# S32M24x register map
Vendor: NXP Semiconductors; File version: 1.5
CPU: CM4 r0p1, little endian, MPU, FPU, VTOR, 4 interrupt priority bits
Registers are 32-bit, read-write, reset 0x0 unless marked. A register's access mark holds for its fields unless they carry their own. Offsets are from the block's base; [hi:lo] are bit positions; {n}, {i} and the like mark numbered series; 'fields as' and 'values as' point back to an identical list.

## PDB0 — PDB
Base 0x40036000
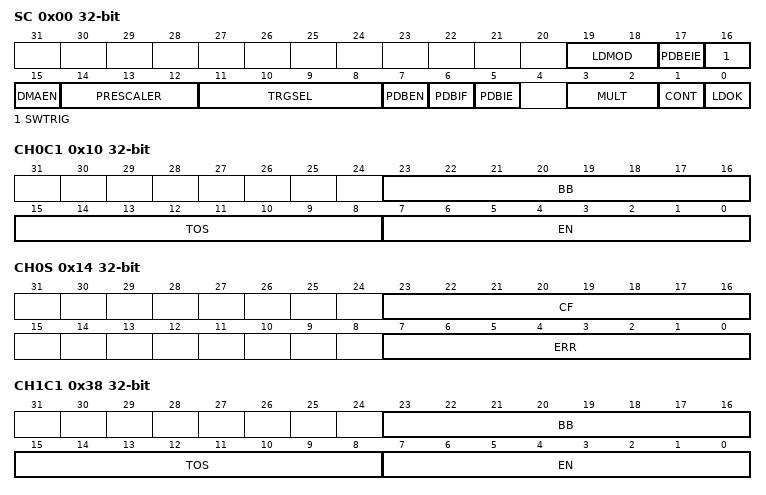
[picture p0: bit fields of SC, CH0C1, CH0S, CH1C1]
0x00 SC — Status and Control register
  [19:18] LDMOD — Load Mode Select
    0=The internal registers are loaded with the values from their buffers, immediately after 1 is written to LDOK; 1=The internal registers are loaded with the values from their buffers when the PDB counter (CNT) = MOD + 1 CNT delay elapsed, after 1 is written to LDOK; 2=The internal registers are loaded with the values from their buffers when a trigger input event is detected, after 1 is written to LDOK; 3=The internal registers are loaded with the values from their buffers when either the PDB counter (CNT) = MOD + 1 CNT delay elapsed, or a trigger input event is detected, after 1 is written to LDOK
  [17] PDBEIE — PDB Sequence Error Interrupt Enable
    0=PDB sequence error interrupt disabled; 1=PDB sequence error interrupt enabled
  [16] SWTRIG — Software Trigger
  [15] DMAEN — DMA Enable
    0=DMA disabled; 1=DMA enabled
  [14:12] PRESCALER — Prescaler Divider Select
    0=Counting uses the peripheral clock divided by MULT (the multiplication factor); 1=Counting uses the peripheral clock divided by 2 x MULT (the multiplication factor); 2=Counting uses the peripheral clock divided by 4 x MULT (the multiplication factor); 3=Counting uses the peripheral clock divided by 8 x MULT (the multiplication factor); 4=Counting uses the peripheral clock divided by 16 x MULT (the multiplication factor); 5=Counting uses the peripheral clock divided by 32 x MULT (the multiplication factor); 6=Counting uses the peripheral clock divided by 64 x MULT (the multiplication factor); 7=Counting uses the peripheral clock divided by 128 x MULT (the multiplication factor)
  [11:8] TRGSEL — Trigger Input Source Select
    {v}=Trigger-In {v} is selected (v=0..14); 15=Software trigger is selected
  [7] PDBEN — PDB Enable
    0=PDB disabled. Counter is off.; 1=PDB enabled
  [6] PDBIF — PDB Interrupt Flag
  [5] PDBIE — PDB Interrupt Enable
    0=PDB interrupt disabled; 1=PDB interrupt enabled
  [3:2] MULT — Multiplication Factor Select for Prescaler
    0=Multiplication factor is 1; 1=Multiplication factor is 10; 2=Multiplication factor is 20; 3=Multiplication factor is 40
  [1] CONT — Continuous Mode Enable
    0=PDB operation in One-Shot mode; 1=PDB operation in Continuous mode
  [0] LDOK — Load OK
0x04 MOD reset 0xFFFF — Modulus register
  [15:0] MOD — PDB Modulus
0x08 CNT ro — Counter register
  [15:0] CNT — PDB Counter
0x0C IDLY reset 0xFFFF — Interrupt Delay register
  [15:0] IDLY — PDB Interrupt Delay
0x10 CH0C1 — Channel n Control register 1
  [23:16] BB — PDB Channel Pre-Trigger Back-to-Back Operation Enable
    0=PDB channel's corresponding pre-trigger back-to-back operation disabled; 1=PDB channel's corresponding pre-trigger back-to-back operation enabled
  [15:8] TOS — PDB Channel Pre-Trigger Output Select
    0=PDB channel's corresponding pre-trigger is in bypassed mode. The pre-trigger asserts one peripheral clock cycle after a rising edge is detected on selected trigger input source or software trigger is selected and SWTRIG is written with 1.; 1=PDB channel's corresponding pre-trigger asserts when the counter reaches the channel delay register and one peripheral clock cycle after a rising edge is detected on selected trigger input source or software trigger is selected and SWTRIG is written with 1
  [7:0] EN — PDB Channel Pre-Trigger Enable
    0=PDB channel's corresponding pre-trigger disabled; 1=PDB channel's corresponding pre-trigger enabled
0x14 CH0S — Channel n Status register
  [23:16] CF — PDB Channel Flags
  [7:0] ERR — PDB Channel Sequence Error Flags
    0=Sequence error not detected on PDB channel's corresponding pre-trigger; 1=Sequence error detected on PDB channel's corresponding pre-trigger. ADCn block can be triggered for a conversion by one pre-trigger from PDB channel n. When one conversion, which is triggered by one of the pre-triggers from PDB channel n, is in progress, new trigger from PDB channel's corresponding pre-trigger m cannot be accepted by ADCn, and ERR[m] is set. Writing 0's to clear the sequence error flags.
0x18 CH0DLY0 — Channel n Delay 0 register
  [15:0] DLY — PDB Channel Delay
0x1C CH0DLY1 — Channel n Delay 1 register
  [15:0] DLY — PDB Channel Delay
0x38 CH1C1 — Channel n Control register 1
  fields as CH0C1
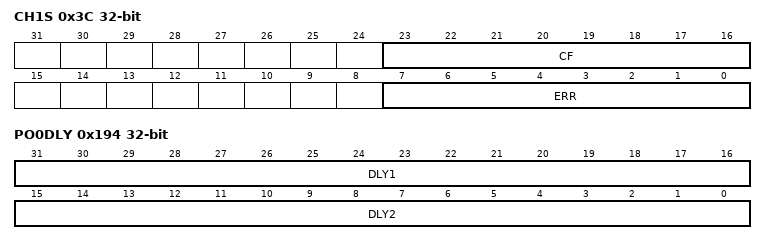
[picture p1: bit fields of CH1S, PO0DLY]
0x3C CH1S — Channel n Status register
  fields as CH0S
0x40 CH1DLY0 — Channel n Delay 0 register
  [15:0] DLY — PDB Channel Delay
0x44 CH1DLY1 — Channel n Delay 1 register
  [15:0] DLY — PDB Channel Delay
0x190 POEN — Pulse-Out n Enable register
  [7:0] POEN — PDB Pulse-Out Enable
    0=PDB Pulse-Out disabled; 1=PDB Pulse-Out enabled
0x194 PO0DLY — Pulse-Out n Delay register
  [31:16] DLY1 — PDB Pulse-Out Delay 1
  [15:0] DLY2 — PDB Pulse-Out Delay 2
